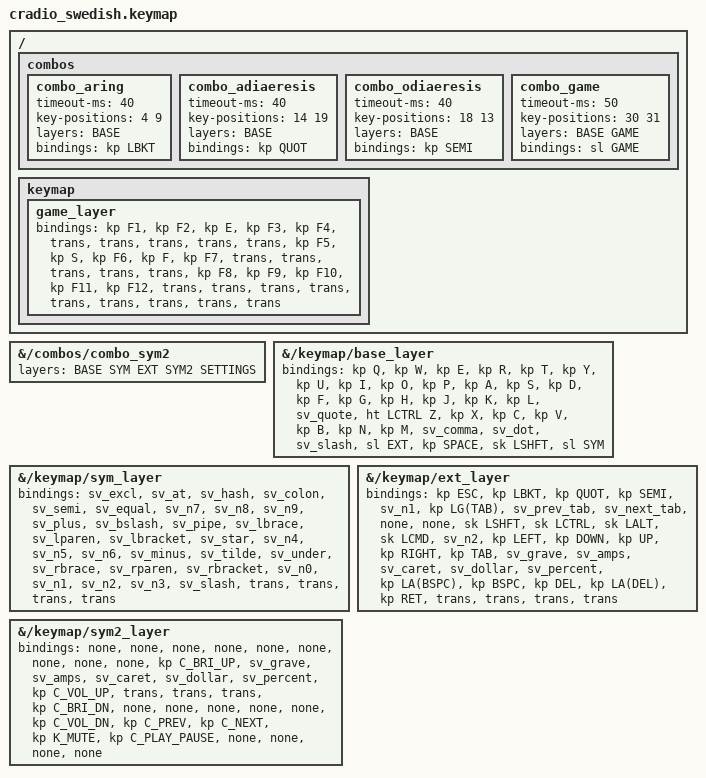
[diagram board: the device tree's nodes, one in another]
// SPDX-License-Identifier: MIT
// Swedish Windows/Linux variant. Inherit the original layers and settings.
#include "cradio.keymap"
#include "swedish.dtsi"

#define GAME 5

/ {
    combos {
        // Letter chords are base-only, so they cannot consume gaming inputs.
        combo_aring {
            timeout-ms = <40>;
            key-positions = <4 9>; // T + P
            layers = <BASE>;
            bindings = <&kp LBKT>;
        };
        combo_adiaeresis {
            timeout-ms = <40>;
            key-positions = <14 19>; // G + apostrophe
            layers = <BASE>;
            bindings = <&kp QUOT>;
        };
        combo_odiaeresis {
            timeout-ms = <40>;
            key-positions = <18 13>; // L + F
            layers = <BASE>;
            bindings = <&kp SEMI>;
        };
        // Tap/release for one Gaming key; hold to keep Gaming active.
        // On SYM, this chord still holds Settings instead (inherited combo).
        combo_game {
            timeout-ms = <50>;
            key-positions = <30 31>;
            layers = <BASE GAME>;
            bindings = <&sl GAME>;
        };
    };

    keymap {
        game_layer {
            // E / S / F retain their base positions. The other twelve left
            // positions are F1-F12, in row order. Right hand/thumbs inherit Base.
            bindings = <
                &kp F1    &kp F2    &kp E     &kp F3    &kp F4     &trans &trans &trans &trans &trans
                &kp F5    &kp S     &kp F6    &kp F     &kp F7     &trans &trans &trans &trans &trans
                &kp F8    &kp F9    &kp F10   &kp F11   &kp F12    &trans &trans &trans &trans &trans
                                             &trans    &trans     &trans &trans
            >;
        };
    };
};

// Keep Media below Gaming from being activated by the other thumb chord.
&{/combos/combo_sym2} {
    layers = <BASE SYM EXT SYM2 SETTINGS>;
};

&{/keymap/base_layer} {
    bindings = <
        &kp Q         &kp W       &kp E       &kp R       &kp T       &kp Y       &kp U       &kp I       &kp O       &kp P
        &kp A         &kp S       &kp D       &kp F       &kp G       &kp H       &kp J       &kp K       &kp L       &sv_quote
        &ht LCTRL Z   &kp X       &kp C       &kp V       &kp B       &kp N       &kp M       &sv_comma   &sv_dot     &sv_slash
                                             &sl EXT     &kp SPACE   &sk LSHFT   &sl SYM
    >;
};

&{/keymap/sym_layer} {
    bindings = <
        // !          @           #           :           ;           =           7           8           9           +
        &sv_excl      &sv_at      &sv_hash    &sv_colon   &sv_semi    &sv_equal   &sv_n7      &sv_n8      &sv_n9      &sv_plus
        // backslash  |           {           (           [           *           4           5           6           -
        &sv_bslash    &sv_pipe    &sv_lbrace  &sv_lparen  &sv_lbracket &sv_star   &sv_n4      &sv_n5      &sv_n6      &sv_minus
        // ~          _           }           )           ]           0           1           2           3           /
        &sv_tilde     &sv_under   &sv_rbrace  &sv_rparen  &sv_rbracket &sv_n0     &sv_n1      &sv_n2      &sv_n3      &sv_slash
                                             &trans      &trans      &trans      &trans
    >;
};

&{/keymap/ext_layer} {
    bindings = <
        &kp ESC       &kp LBKT    &kp QUOT    &kp SEMI    &sv_n1      &kp LG(TAB) &sv_prev_tab &sv_next_tab &none       &none
        &sk LSHFT     &sk LCTRL   &sk LALT    &sk LCMD    &sv_n2      &kp LEFT    &kp DOWN    &kp UP      &kp RIGHT   &kp TAB
        &sv_grave     &sv_amps    &sv_caret   &sv_dollar  &sv_percent &kp LA(BSPC) &kp BSPC   &kp DEL     &kp LA(DEL) &kp RET
                                             &trans      &trans      &trans      &trans
    >;
};

&{/keymap/sym2_layer} {
    bindings = <
        &none         &none       &none       &none       &none       &none       &none       &none       &none       &kp C_BRI_UP
        // `          &           ^           $           %
        &sv_grave     &sv_amps    &sv_caret   &sv_dollar  &sv_percent &kp C_VOL_UP &trans     &trans      &trans      &kp C_BRI_DN
        &none         &none       &none       &none       &none       &kp C_VOL_DN &kp C_PREV &kp C_NEXT  &kp K_MUTE  &kp C_PLAY_PAUSE
                                             &none       &none       &none       &none
    >;
};
